# STM32H5F5xx register map
File version: 1.0
Registers are 32-bit, read-write, reset 0x0 unless marked. A register's access mark holds for its fields unless they carry their own. Offsets are from the block's base; [hi:lo] are bit positions; {n}, {i} and the like mark numbered series.

## DTS
Base 0x40008C00
Same registers: DTS_S 0x50008C00
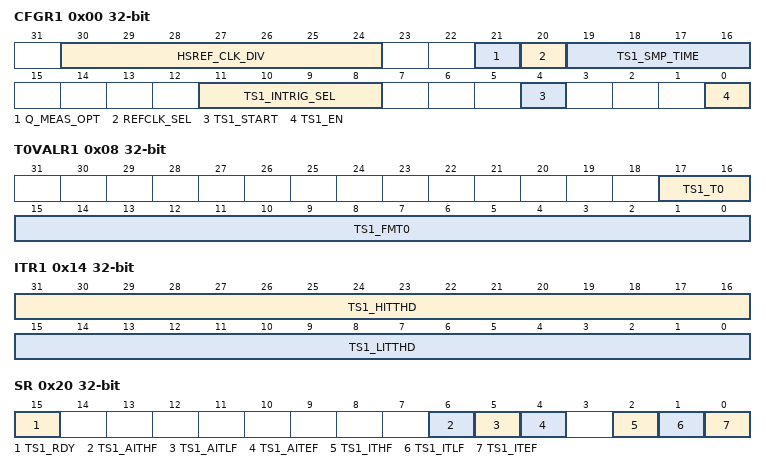
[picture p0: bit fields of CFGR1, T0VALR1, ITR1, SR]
0x00 CFGR1 — DTS configuration register
  [30:24] HSREF_CLK_DIV — High Speed Clock Divider Ratio [6:0]
  [21] Q_MEAS_OPT — Quick measure option bit
  [20] REFCLK_SEL — Reference Clock Selection
  [19:16] TS1_SMP_TIME — Sample time [3:0] for DTS
  [11:8] TS1_INTRIG_SEL — Input triggers selection bits [3:0] for DTS
  [4] TS1_START — Proceed to a frequency measurement on DTS
  [0] TS1_EN — DTS Enable
0x08 T0VALR1 — DTS T0 Value register
  [17:16] TS1_T0 — Engineering value of the DTSerature T0 for DTS
  [15:0] TS1_FMT0 — Engineering value of the measured frequency at T0 for DTS
0x10 RAMPVALR — DTS Ramp value register
  [15:0] TS1_RAMP_COEFF — Engineering value of the ramp coefficient for DTS
0x14 ITR1 — DTS Interrupt threshold register
  [31:16] TS1_HITTHD — High interrupt threshold[15:0] for DTS
  [15:0] TS1_LITTHD — Low interrupt threshold[15:0] for DTS
0x1C DR — DTS data register
  [15:0] TS1_MFREQ — Measured Frequency[15:0] for DTS
0x20 SR — DTS status register
  [15] TS1_RDY — DTS ready flag
  [6] TS1_AITHF — Asynchronous interrupt flag for high threshold for DTS
  [5] TS1_AITLF — Asynchronous interrupt flag for low threshold for DTS
  [4] TS1_AITEF — Asynchronous interrupt flag for end of measure for DTS
  [2] TS1_ITHF — Interrupt flag for high threshold for DTS
  [1] TS1_ITLF — Interrupt flag for low threshold for DTS
  [0] TS1_ITEF — Interrupt flag for end of measure for DTS
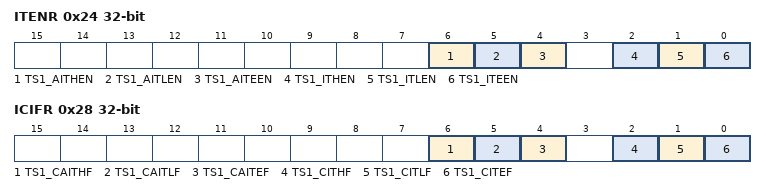
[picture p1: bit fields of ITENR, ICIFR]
0x24 ITENR — DTS Interrupt enable register
  [6] TS1_AITHEN — Enable asynchronous interrupt flag for high threshold for DTS
  [5] TS1_AITLEN — Enable Asynchronous interrupt flag for low threshold for DTS
  [4] TS1_AITEEN — Enable asynchronous interrupt flag for end of measure for DTS
  [2] TS1_ITHEN — Enable interrupt flag for high threshold for DTS
  [1] TS1_ITLEN — Enable interrupt flag for low threshold for DTS
  [0] TS1_ITEEN — Enable interrupt flag for end of measure for DTS
0x28 ICIFR — DTS Clear Interrupt flag register
  [6] TS1_CAITHF — Clear the asynchronous IT flag for high threshold on DTS
  [5] TS1_CAITLF — Clear the asynchronous IT flag for low threshold for DTS
  [4] TS1_CAITEF — Clear the asynchronous IT flag for End Of Measure for DTS
  [2] TS1_CITHF — Clear the IT flag for high threshold on DTS
  [1] TS1_CITLF — Clear the IT flag for low threshold for DTS
  [0] TS1_CITEF — Clear the IT flag for End Of Measure for DTS
0x2C OR — DTS option register 1

## FDCAN_CONFIG — FD Controller Area Network Configuration
Base 0x4000A500
Same registers: FDCAN_CONFIG_S 0x5000A500
0x00 CKDIV — FDCAN clock divider register
  [3:0] PDIV — Input Clock Divider
0x204 OPTR — FDCAN option register
0x2F0 HWCFG — FDCAN hardware configuration register
0x2F4 VERR — FDCAN IP version register
0x2F8 IPIDR — FDCAN IP ID register
0x2FC SIDR — FDCAN size ID register

## GFXTIM
Base 0x40017400
Same registers: GFXTIM_S 0x50017400
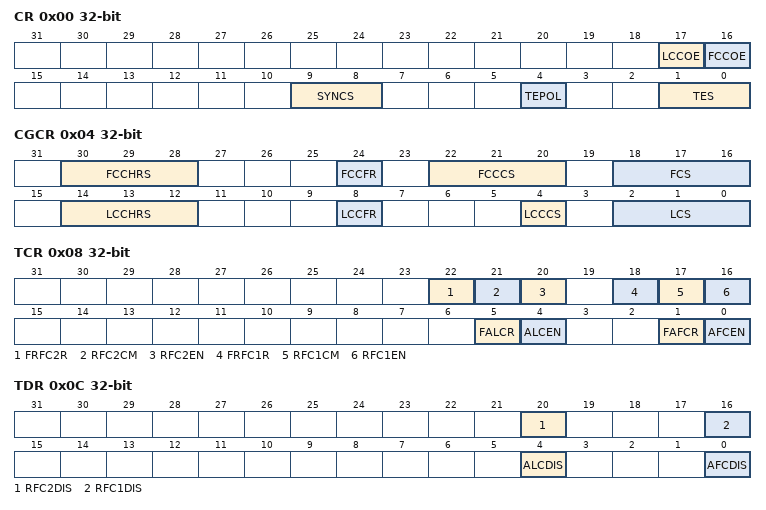
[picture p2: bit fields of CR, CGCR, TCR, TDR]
0x00 CR — GFXTIM configuration register
  [17] LCCOE, [16] FCCOE, [9:8] SYNCS, [4] TEPOL, [1:0] TES
0x04 CGCR — GFXTIM clock generator configuration register
  [30:28] FCCHRS, [24] FCCFR, [22:20] FCCCS, [18:16] FCS, [14:12] LCCHRS, [8] LCCFR, [4] LCCCS, [2:0] LCS
0x08 TCR — GFXTIM timers configuration register
  [22] FRFC2R, [21] RFC2CM, [20] RFC2EN, [18] FRFC1R, [17] RFC1CM, [16] RFC1EN, [5] FALCR, [4] ALCEN, [1] FAFCR, [0] AFCEN
0x0C TDR — GFXTIM timers disable register
  [20] RFC2DIS, [16] RFC1DIS, [4] ALCDIS, [0] AFCDIS
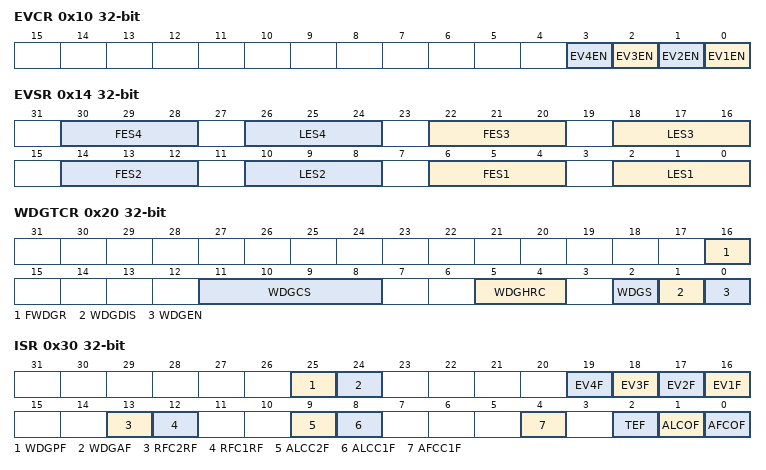
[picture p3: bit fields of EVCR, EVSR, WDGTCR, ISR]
0x10 EVCR — GFXTIM events control register
  [n-1] EV{n}EN (n=1..4)
0x14 EVSR — GFXTIM events selection register
  [8n-2:8n-4] FES{n} (n=1..4), [8n-6:8n-8] LES{n} (n=1..4)
0x20 WDGTCR — GFXTIM watchdog timer configuration register
  [16] FWDGR, [11:8] WDGCS, [5:4] WDGHRC, [2] WDGS, [1] WDGDIS, [0] WDGEN
0x30 ISR — GFXTIM interrupt status register
  [25] WDGPF, [24] WDGAF, [n+15] EV{n}F (n=1..4), [13] RFC2RF, [12] RFC1RF, [9] ALCC2F, [8] ALCC1F, [4] AFCC1F, [2] TEF, [1] ALCOF, [0] AFCOF
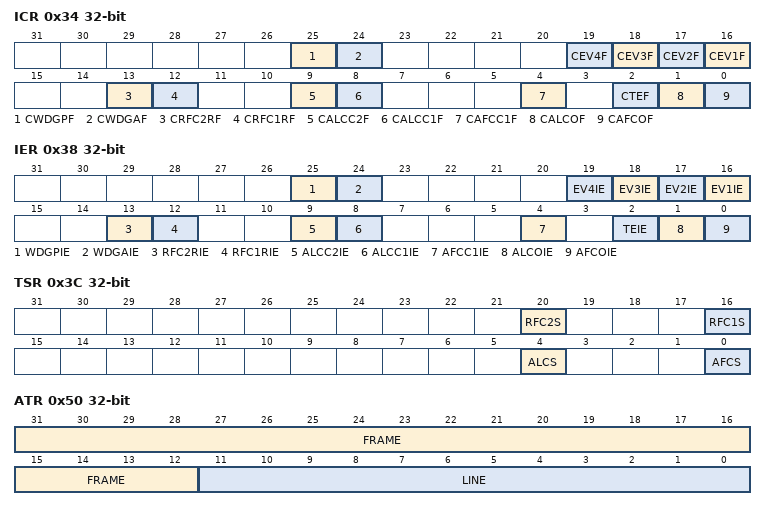
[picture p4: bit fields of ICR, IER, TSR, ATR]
0x34 ICR — GFXTIM interrupt clear register
  [25] CWDGPF, [24] CWDGAF, [n+15] CEV{n}F (n=1..4), [13] CRFC2RF, [12] CRFC1RF, [9] CALCC2F, [8] CALCC1F, [4] CAFCC1F, [2] CTEF, [1] CALCOF, [0] CAFCOF
0x38 IER — GFXTIM interrupt enable register
  [25] WDGPIE, [24] WDGAIE, [n+15] EV{n}IE (n=1..4), [13] RFC2RIE, [12] RFC1RIE, [9] ALCC2IE, [8] ALCC1IE, [4] AFCC1IE, [2] TEIE, [1] ALCOIE, [0] AFCOIE
0x3C TSR — GFXTIM timers status register
  [20] RFC2S, [16] RFC1S, [4] ALCS, [0] AFCS
0x40 LCCRR — GFXTIM line clock counter reload register
  [21:0] RELOAD
0x44 FCCRR — GFXTIM frame clock counter reload register
  [11:0] RELOAD
0x50 ATR — GFXTIM absolute time register
  [31:12] FRAME, [11:0] LINE
0x54 AFCR — GFXTIM absolute frame counter register
  [19:0] FRAME
0x58 ALCR — GFXTIM absolute line counter register
  [11:0] LINE
0x60 AFCC1R — GFXTIM absolute frame counter compare 1 register
  [19:0] FRAME
0x70 ALCC1R — GFXTIM absolute line counter compare 1 register
  [11:0] LINE
0x74 ALCC2R — GFXTIM absolute line counter compare 2 register
  [11:0] LINE
0x80 RFC1R — GFXTIM relative frame counter 1 register
  [11:0] FRAME
0x84 RFC1RR — GFXTIM relative frame counter 1 reload register
  [11:0] FRAME
0x88 RFC2R — GFXTIM relative frame counter 2 register
  [11:0] FRAME
0x8C RFC2RR — GFXTIM relative frame counter 2 reload register
  [11:0] FRAME
0xA0 WDGCR — GFXTIM watchdog counter register
  [15:0] VALUE
0xA4 WDGRR — GFXTIM watchdog reload register
  [15:0] RELOAD
0xA8 WDGPAR — GFXTIM watchdog pre-alarm register
  [15:0] PREALARM
0x3F0 HWCFGR — GFXTIM HW configuration register
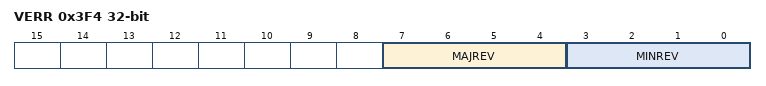
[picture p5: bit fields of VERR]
0x3F4 VERR — GFXTIM version register
  [7:4] MAJREV, [3:0] MINREV
0x3F8 IPIDR — GFXTIM identification register
  [31:0] ID
0x3FC SIDR — GFXTIM size identification register
  [31:0] SID
